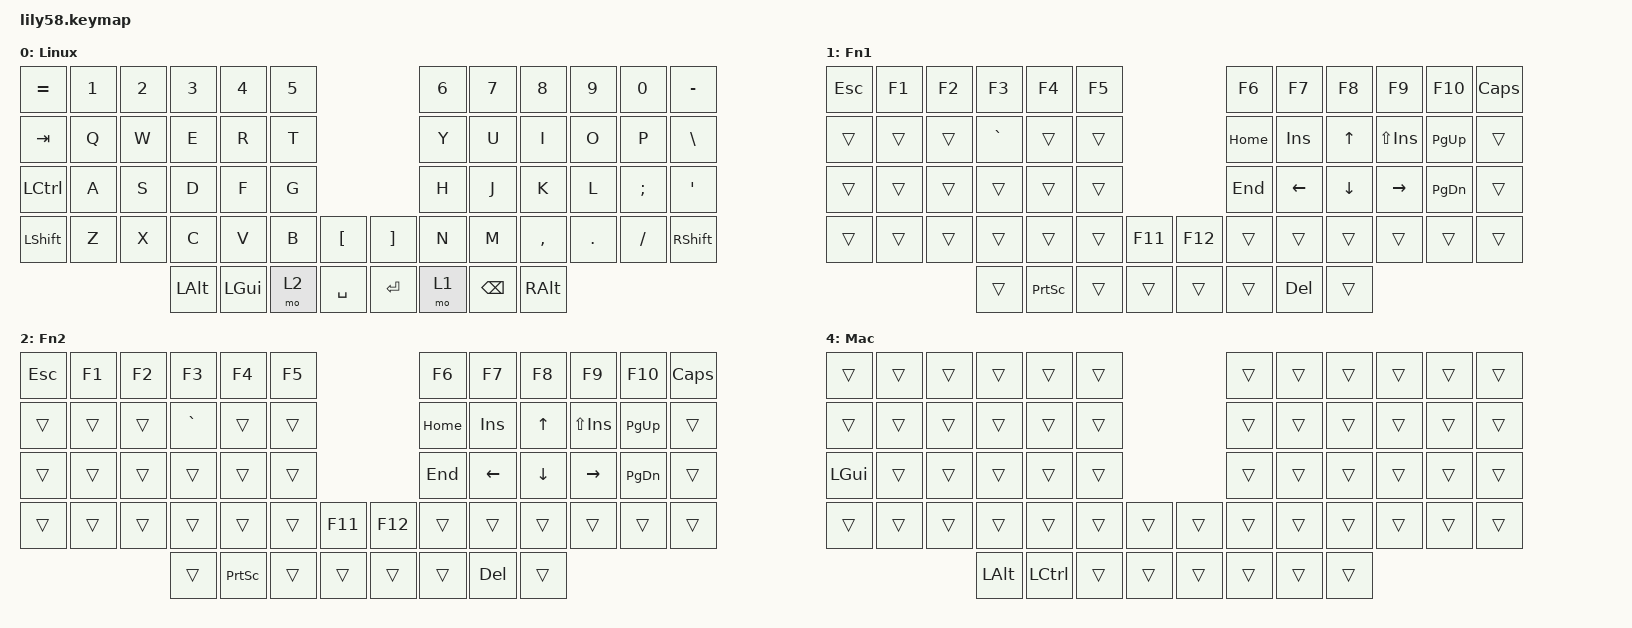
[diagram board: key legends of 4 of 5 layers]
/*
 * Copyright (c) 2020 The ZMK Contributors
 *
 * SPDX-License-Identifier: MIT
 */

#include <behaviors.dtsi>
#include <dt-bindings/zmk/keys.h>
#include <dt-bindings/zmk/bt.h>
#include <dt-bindings/zmk/ext_power.h>

/ {
    macros {
        bt_linux: bt_linux {
            compatible = "zmk,behavior-macro";
            #binding-cells = <0>;
            bindings = <&bt BT_SEL 0>, <&to 0>;
        };

        bt_mac: bt_mac {
            compatible = "zmk,behavior-macro";
            #binding-cells = <0>;
            bindings = <&bt BT_SEL 1>, <&to 4>;
        };
    };

    conditional_layers {
        compatible = "zmk,conditional-layers";
        tri_layer {
            if-layers = <1 2>;
            then-layer = <3>;
        };
    };

    combos {
        compatible = "zmk,combos";
        combo_mac_toggle {
            timeout-ms = <50>;
            key-positions = <50 57>;
            bindings = <&tog 4>;
        };
    };

    keymap {
        compatible = "zmk,keymap";

        def_layer {
            display-name = "Linux";
            bindings = <
&kp EQUAL &kp N1 &kp N2 &kp N3   &kp N4   &kp N5                     &kp N6 &kp N7   &kp N8    &kp N9  &kp N0   &kp MINUS
&kp TAB   &kp Q  &kp W  &kp E    &kp R    &kp T                      &kp Y  &kp U    &kp I     &kp O   &kp P    &kp BSLH
&kp LCTRL &kp A  &kp S  &kp D    &kp F    &kp G                      &kp H  &kp J    &kp K     &kp L   &kp SEMI &kp SQT
&kp LSHFT &kp Z  &kp X  &kp C    &kp V    &kp B  &kp LBKT   &kp RBKT &kp N  &kp M    &kp COMMA &kp DOT &kp FSLH &kp RSHFT
                        &kp LALT &kp LGUI &mo 2  &kp SPACE  &kp RET  &mo 1  &kp BSPC &kp RALT
            >;

            sensor-bindings = <&inc_dec_kp C_VOL_UP C_VOL_DN>;
        };

        fn1_layer {
            display-name = "Fn1";
            bindings = <
&kp ESC    &kp F1  &kp F2  &kp F3    &kp F4     &kp F5                    &kp F6    &kp F7    &kp F8    &kp F9       &kp F10    &kp CAPS
&trans     &trans  &trans  &kp GRAVE &trans     &trans                    &kp HOME  &kp INS   &kp UP    &kp LS(INS)  &kp PG_UP  &trans
&trans     &trans  &trans  &trans    &trans     &trans                    &kp END   &kp LEFT  &kp DOWN  &kp RIGHT    &kp PG_DN  &trans
&trans     &trans  &trans  &trans    &trans     &trans  &kp F11  &kp F12  &trans    &trans    &trans    &trans       &trans     &trans
                           &trans    &kp PSCRN  &trans  &trans   &trans   &trans    &kp DEL   &trans
            >;

            sensor-bindings = <&inc_dec_kp C_VOL_UP C_VOL_DN>;
        };

        fn2_layer {
            display-name = "Fn2";
            bindings = <
&kp ESC    &kp F1  &kp F2  &kp F3    &kp F4     &kp F5                    &kp F6    &kp F7    &kp F8    &kp F9       &kp F10    &kp CAPS
&trans     &trans  &trans  &kp GRAVE &trans     &trans                    &kp HOME  &kp INS   &kp UP    &kp LS(INS)  &kp PG_UP  &trans
&trans     &trans  &trans  &trans    &trans     &trans                    &kp END   &kp LEFT  &kp DOWN  &kp RIGHT    &kp PG_DN  &trans
&trans     &trans  &trans  &trans    &trans     &trans  &kp F11  &kp F12  &trans    &trans    &trans    &trans       &trans     &trans
                           &trans    &kp PSCRN  &trans  &trans   &trans   &trans    &kp DEL   &trans
            >;

            sensor-bindings = <&inc_dec_kp C_VOL_UP C_VOL_DN>;
        };

        fn3_layer {
            display-name = "Fn3";
            bindings = <
&trans     &kp C_BRI_DN &kp C_BRI_UP &kp LC(UP)   &kp LG(SPACE) &trans                &trans       &kp C_PREV &kp C_PP   &kp C_NEXT &kp C_MUTE &trans
&bt BT_CLR &bt_linux    &bt_mac      &bt BT_SEL 2 &bt BT_SEL 3  &bt BT_SEL 4          &trans       &trans     &trans     &trans     &trans     &trans
&trans     &trans       &trans       &trans       &trans        &trans                &trans       &trans     &trans     &trans     &trans     &trans
&trans     &trans       &trans       &trans       &trans        &trans  &kp C_VOL_DN  &kp C_VOL_UP &trans     &trans     &trans     &trans     &trans
                                     &trans       &trans        &trans  &trans        &trans       &trans     &trans     &trans
            >;

            sensor-bindings = <&inc_dec_kp C_VOL_UP C_VOL_DN>;
        };

        mac_layer {
            display-name = "Mac";
            bindings = <
&trans    &trans  &trans  &trans    &trans    &trans                   &trans  &trans  &trans  &trans  &trans  &trans
&trans    &trans  &trans  &trans    &trans    &trans                   &trans  &trans  &trans  &trans  &trans  &trans
&kp LGUI  &trans  &trans  &trans    &trans    &trans                   &trans  &trans  &trans  &trans  &trans  &trans
&trans    &trans  &trans  &trans    &trans    &trans  &trans   &trans  &trans  &trans  &trans  &trans  &trans  &trans
                          &kp LALT  &kp LCTRL &trans  &trans   &trans  &trans  &trans  &trans
            >;

            sensor-bindings = <&inc_dec_kp C_VOL_UP C_VOL_DN>;
        };
    };
};
